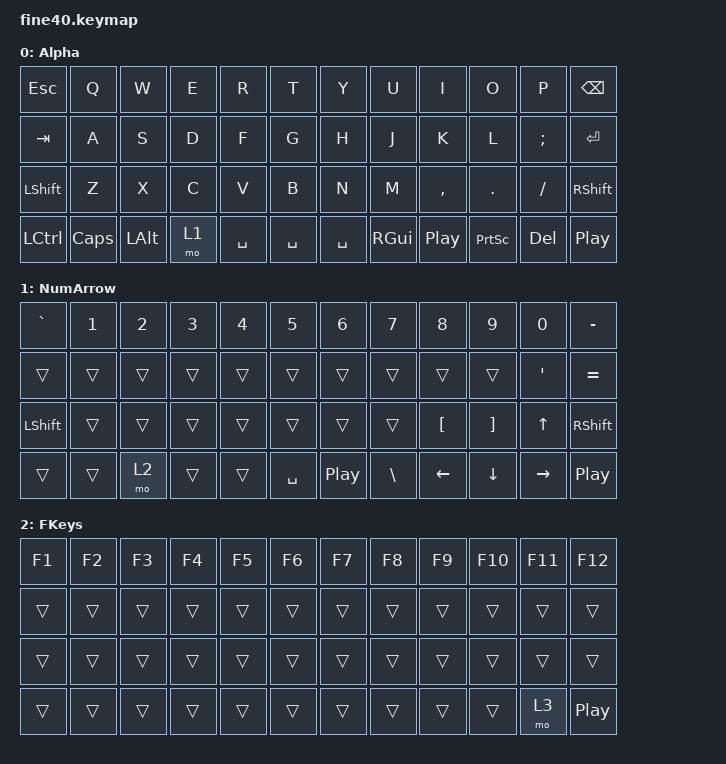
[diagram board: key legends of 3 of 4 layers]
/*
 * Aidan Smith (2021)
 *
 * SPDX-License-Identifier: MIT
 */ 

#include <behaviors.dtsi>
#include <dt-bindings/zmk/keys.h>
#include <dt-bindings/zmk/bt.h>
#include <dt-bindings/zmk/ext_power.h>

/ {
	keymap {
		compatible = "zmk,keymap";

		default_layer {
		     label = "Alpha";
			bindings = <
				&kp ESC    &kp Q     &kp W      &kp E       &kp R      &kp T      &kp Y       &kp U     &kp I      &kp O      &kp P      &kp BSPC
				&kp TAB    &kp A     &kp S      &kp D       &kp F      &kp G      &kp H       &kp J     &kp K      &kp L      &kp SEMI   &kp RET
				&kp LSHFT  &kp Z     &kp X      &kp C       &kp V      &kp B      &kp N       &kp M     &kp COMMA  &kp DOT    &kp FSLH   &kp RSHFT
				&kp LCTL   &kp CAPS  &kp LALT   &mo 1       &kp SPACE  &kp SPACE  &kp SPACE   &kp RGUI  &kp C_PP   &kp PSCRN  &kp DEL    &kp C_PP
			>;

			sensor-bindings = <&inc_dec_kp C_VOL_UP C_VOL_DN>;
		};

		right {
		     label = "NumArrow";
			bindings = <
				&kp GRAVE   &kp N1   &kp N2    &kp N3   &kp N4     &kp N5     &kp N6     &kp N7      &kp N8      &kp N9      &kp N0     &kp MINUS
				&trans      &trans   &trans    &trans   &trans     &trans     &trans     &trans      &trans      &trans      &kp APOS   &kp EQUAL
				&kp LSHFT   &trans   &trans    &trans   &trans     &trans     &trans     &trans      &kp LBKT    &kp RBKT    &kp UP     &kp RSHFT
				&trans      &trans   &mo 2     &trans   &trans     &kp SPACE  &kp C_PP   &kp BSLH    &kp LEFT    &kp DOWN    &kp RIGHT  &kp C_PP  
			>;
			
			sensor-bindings = <&inc_dec_kp LC(PLUS) LC(MINUS)>;
		};

		left {
		     label = "FKeys";
			bindings = <
				&kp F1      &kp F2   &kp F3   &kp F4   &kp F5     &kp F6     &kp F7     &kp F8      &kp F9      &kp F10     &kp F11    &kp F12
				&trans      &trans   &trans   &trans   &trans     &trans     &trans     &trans      &trans      &trans      &trans     &trans
				&trans      &trans   &trans   &trans   &trans     &trans     &trans     &trans      &trans      &trans      &trans     &trans
				&trans      &trans   &trans   &trans   &trans     &trans     &trans     &trans      &trans      &trans      &mo 3      &kp C_PP  
			>;
		};

		control {
		     label = "Sys/BT";
			bindings = <
				&sys_reset      &trans      &trans     &bt BT_PRV &bt BT_NXT &trans  &trans  &trans  &trans  &trans  &trans  &bt BT_CLR
				&trans          &trans      &trans     &trans     &trans     &trans  &trans  &trans  &trans  &trans  &trans  &trans
				&trans          &trans      &trans     &trans     &trans     &trans  &trans  &trans  &trans  &trans  &trans  &trans
				&bootloader     &trans      &trans     &trans     &trans     &trans  &trans  &trans  &trans  &trans  &trans  
			>;
		};
	};
};
